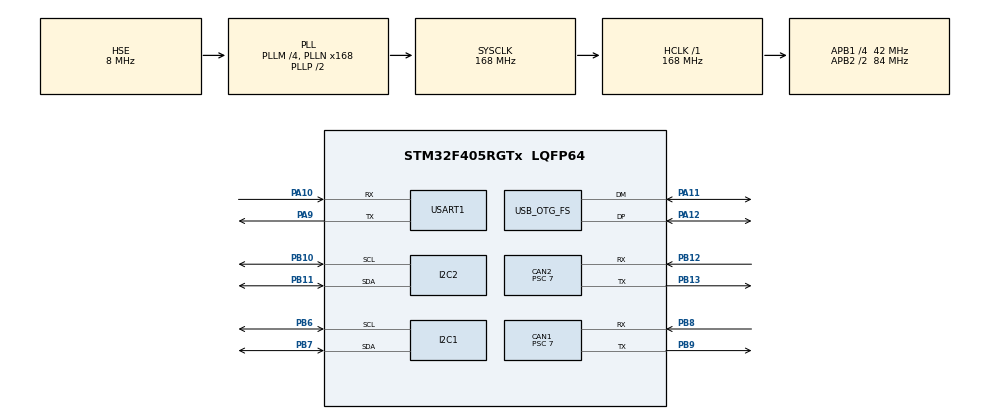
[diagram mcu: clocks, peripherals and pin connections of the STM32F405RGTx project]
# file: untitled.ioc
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CAN1.AWUM=ENABLE
CAN1.BS1=CAN_BS1_3TQ
CAN1.BS2=CAN_BS2_2TQ
CAN1.CalculateBaudRate=999999
CAN1.CalculateTimeBit=1000
CAN1.CalculateTimeQuantum=166.66666666666669
CAN1.Prescaler=7
CAN1.TXFP=ENABLE
CAN2.AWUM=ENABLE
CAN2.BS1=CAN_BS1_3TQ
CAN2.BS2=CAN_BS2_2TQ
CAN2.CalculateBaudRate=999999
CAN2.CalculateTimeBit=1000
CAN2.CalculateTimeQuantum=166.66666666666669
CAN2.Prescaler=7
CAN2.TXFP=ENABLE
FREERTOS.Tasks01=defaultTask,24,500,StartDefaultTask,Default,NULL,Dynamic,NULL,NULL
FREERTOS.configENABLE_FPU=1
FREERTOS.configTOTAL_HEAP_SIZE=65535
I2C1.I2C_Mode=I2C_Fast
I2C2.I2C_Mode=I2C_Fast
Mcu.Family=STM32F4
Mcu.Name=STM32F405RGTx
Mcu.Package=LQFP64
NVIC.CAN1_RX0_IRQn=true\:5\:0\:false\:false\:true\:true\:true\:true\:true
NVIC.CAN1_RX1_IRQn=true\:5\:0\:false\:false\:true\:true\:true\:true\:true
NVIC.CAN1_SCE_IRQn=true\:5\:0\:false\:false\:true\:true\:true\:true\:true
NVIC.CAN1_TX_IRQn=true\:5\:0\:false\:false\:true\:true\:true\:true\:true
NVIC.CAN2_RX0_IRQn=true\:5\:0\:false\:false\:true\:true\:true\:true\:true
NVIC.CAN2_RX1_IRQn=true\:5\:0\:false\:false\:true\:true\:true\:true\:true
NVIC.CAN2_SCE_IRQn=true\:5\:0\:false\:false\:true\:true\:true\:true\:true
NVIC.CAN2_TX_IRQn=true\:5\:0\:false\:false\:true\:true\:true\:true\:true
NVIC.OTG_FS_IRQn=true\:5\:0\:false\:false\:true\:true\:true\:true\:true
NVIC.PriorityGroup=NVIC_PRIORITYGROUP_4
NVIC.TIM6_DAC_IRQn=true\:15\:0\:false\:false\:true\:false\:false\:true\:true
NVIC.TIM8_TRG_COM_TIM14_IRQn=true\:5\:0\:false\:false\:true\:true\:true\:true\:true
NVIC.TimeBase=TIM6_DAC_IRQn
NVIC.TimeBaseIP=TIM6
NVIC.USART1_IRQn=true\:5\:0\:false\:false\:true\:true\:true\:true\:true
PA10.Mode=Asynchronous
PA10.Signal=USART1_RX
PA11.Mode=Device_Only
PA11.Signal=USB_OTG_FS_DM
PA12.Mode=Device_Only
PA12.Signal=USB_OTG_FS_DP
PA13.Mode=Serial_Wire
PA13.Signal=SYS_JTMS-SWDIO
PA14.Mode=Serial_Wire
PA14.Signal=SYS_JTCK-SWCLK
PA9.Mode=Asynchronous
PA9.Signal=USART1_TX
PB10.Mode=I2C
PB10.Signal=I2C2_SCL
PB11.Mode=I2C
PB11.Signal=I2C2_SDA
PB12.Mode=CAN_Activate
PB12.Signal=CAN2_RX
PB13.Mode=CAN_Activate
PB13.Signal=CAN2_TX
PB6.Mode=I2C
PB6.Signal=I2C1_SCL
PB7.Mode=I2C
PB7.Signal=I2C1_SDA
PB8.Mode=CAN_Activate
PB8.Signal=CAN1_RX
PB9.Mode=CAN_Activate
PB9.Signal=CAN1_TX
PH0-OSC_IN.Mode=HSE-External-Oscillator
PH0-OSC_IN.Signal=RCC_OSC_IN
PH1-OSC_OUT.Mode=HSE-External-Oscillator
PH1-OSC_OUT.Signal=RCC_OSC_OUT
ProjectManager.HeapSize=0x3C00
ProjectManager.StackSize=0x800
ProjectManager.TargetToolchain=STM32CubeIDE
RCC.48MHZClocksFreq_Value=48000000
RCC.AHBFreq_Value=168000000
RCC.APB1CLKDivider=RCC_HCLK_DIV4
RCC.APB1Freq_Value=42000000
RCC.APB1TimFreq_Value=84000000
RCC.APB2CLKDivider=RCC_HCLK_DIV2
RCC.APB2Freq_Value=84000000
RCC.APB2TimFreq_Value=168000000
RCC.CortexFreq_Value=168000000
RCC.HCLKFreq_Value=168000000
RCC.HSE_VALUE=8000000
RCC.HSI_VALUE=16000000
RCC.LSE_VALUE=32768
RCC.PLLM=4
RCC.PLLN=168
RCC.PLLQ=7
RCC.SYSCLKFreq_VALUE=168000000
RCC.SYSCLKSource=RCC_SYSCLKSOURCE_PLLCLK
RCC.VCOOutputFreq_Value=336000000
USART1.VirtualMode=VM_ASYNC
USB_DEVICE.CLASS_NAME_FS=CDC
USB_DEVICE.VirtualMode-CDC_FS=Cdc
USB_DEVICE.VirtualModeFS=Cdc_FS
USB_OTG_FS.VirtualMode=Device_Only
VP_FREERTOS_VS_CMSIS_V2.Mode=CMSIS_V2
VP_SYS_VS_tim6.Mode=TIM6
VP_TIM14_VS_ClockSourceINT.Mode=Enable_Timer
VP_USB_DEVICE_VS_USB_DEVICE_CDC_FS.Mode=CDC_FS
board=custom

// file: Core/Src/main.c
/* USER CODE BEGIN Header */
/**
  ******************************************************************************
  * @file           : main.c
  * @brief          : Main program body
  ******************************************************************************
  * @attention
  *
  * Copyright (c) 2025 STMicroelectronics.
  * All rights reserved.
  *
  * This software is licensed under terms that can be found in the LICENSE file
  * in the root directory of this software component.
  * If no LICENSE file comes with this software, it is provided AS-IS.
  *
  ******************************************************************************
  */
/* USER CODE END Header */
#include "main.h"
#include "cmsis_os.h"
#include "can.h"
#include "i2c.h"
#include "tim.h"
#include "usart.h"
#include "usb_device.h"
#include "gpio.h"

void SystemClock_Config(void);
void MX_FREERTOS_Init(void);

int main(void)
{

  /* MCU Configuration--------------------------------------------------------*/

  /* Reset of all peripherals, Initializes the Flash interface and the Systick. */
  HAL_Init();

  /* Configure the system clock */
  SystemClock_Config();

  /* Initialize all configured peripherals */
  MX_GPIO_Init();
  MX_CAN1_Init();
  MX_CAN2_Init();
  MX_I2C1_Init();
  MX_USART1_UART_Init();
  MX_I2C2_Init();
  MX_TIM14_Init();

  /* Init scheduler */
  osKernelInitialize();  /* Call init function for freertos objects (in freertos.c) */
  MX_FREERTOS_Init();

  /* Start scheduler */
  osKernelStart();

  /* We should never get here as control is now taken by the scheduler */
  /* Infinite loop */
  while (1)
  {

  }
}

void SystemClock_Config(void)
{
  RCC_OscInitTypeDef RCC_OscInitStruct = {0};
  RCC_ClkInitTypeDef RCC_ClkInitStruct = {0};

  /** Configure the main internal regulator output voltage
  */
  __HAL_RCC_PWR_CLK_ENABLE();
  __HAL_PWR_VOLTAGESCALING_CONFIG(PWR_REGULATOR_VOLTAGE_SCALE1);

  /** Initializes the RCC Oscillators according to the specified parameters
  * in the RCC_OscInitTypeDef structure.
  */
  RCC_OscInitStruct.OscillatorType = RCC_OSCILLATORTYPE_HSE;
  RCC_OscInitStruct.HSEState = RCC_HSE_ON;
  RCC_OscInitStruct.PLL.PLLState = RCC_PLL_ON;
  RCC_OscInitStruct.PLL.PLLSource = RCC_PLLSOURCE_HSE;
  RCC_OscInitStruct.PLL.PLLM = 4;
  RCC_OscInitStruct.PLL.PLLN = 168;
  RCC_OscInitStruct.PLL.PLLP = RCC_PLLP_DIV2;
  RCC_OscInitStruct.PLL.PLLQ = 7;
  if (HAL_RCC_OscConfig(&RCC_OscInitStruct) != HAL_OK)
  {
    Error_Handler();
  }

  /** Initializes the CPU, AHB and APB buses clocks
  */
  RCC_ClkInitStruct.ClockType = RCC_CLOCKTYPE_HCLK|RCC_CLOCKTYPE_SYSCLK
                              |RCC_CLOCKTYPE_PCLK1|RCC_CLOCKTYPE_PCLK2;
  RCC_ClkInitStruct.SYSCLKSource = RCC_SYSCLKSOURCE_PLLCLK;
  RCC_ClkInitStruct.AHBCLKDivider = RCC_SYSCLK_DIV1;
  RCC_ClkInitStruct.APB1CLKDivider = RCC_HCLK_DIV4;
  RCC_ClkInitStruct.APB2CLKDivider = RCC_HCLK_DIV2;

  if (HAL_RCC_ClockConfig(&RCC_ClkInitStruct, FLASH_LATENCY_5) != HAL_OK)
  {
    Error_Handler();
  }
}

void HAL_TIM_PeriodElapsedCallback(TIM_HandleTypeDef *htim)
{
  if (htim->Instance == TIM6) {
    HAL_IncTick();
  }
}

void Error_Handler(void)
{
  __disable_irq();
  while (1)
  {
  }
}

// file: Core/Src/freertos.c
/* USER CODE BEGIN Header */
/**
  ******************************************************************************
  * File Name          : freertos.c
  * Description        : Code for freertos applications
  ******************************************************************************
  * @attention
  *
  * Copyright (c) 2025 STMicroelectronics.
  * All rights reserved.
  *
  * This software is licensed under terms that can be found in the LICENSE file
  * in the root directory of this software component.
  * If no LICENSE file comes with this software, it is provided AS-IS.
  *
  ******************************************************************************
  */
/* USER CODE END Header */

#include "FreeRTOS.h"
#include "task.h"
#include "main.h"
#include "cmsis_os.h"

/* USER CODE BEGIN Includes */
#include "common_inc.h"
/* USER CODE END Includes */

/* Definitions for defaultTask */
osThreadId_t defaultTaskHandle;
const osThreadAttr_t defaultTask_attributes = {
  .name = "defaultTask",
  .stack_size = 500 * 4,
  .priority = (osPriority_t) osPriorityNormal,
};

void StartDefaultTask(void *argument);

extern void MX_USB_DEVICE_Init(void);
void MX_FREERTOS_Init(void); /* (MISRA C 2004 rule 8.1) */

void MX_FREERTOS_Init(void) {

  /* Create the thread(s) */
  /* creation of defaultTask */
  defaultTaskHandle = osThreadNew(StartDefaultTask, NULL, &defaultTask_attributes);

}

void StartDefaultTask(void *argument)
{
  /* init code for USB_DEVICE */
  MX_USB_DEVICE_Init();
  for(;;)
  {
    osDelay(1);
  }
}
